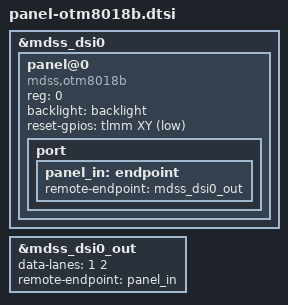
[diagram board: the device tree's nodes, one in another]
&mdss_dsi0 {
	panel@0 {
		compatible = "mdss,otm8018b";
		reg = <0>;

		backlight = <&backlight>;
		reset-gpios = <&tlmm XY GPIO_ACTIVE_LOW>;

		port {
			panel_in: endpoint {
				remote-endpoint = <&mdss_dsi0_out>;
			};
		};
	};
};

&mdss_dsi0_out {
	data-lanes = <1 2>;
	remote-endpoint = <&panel_in>;
};
